# CY8C5888LTI_LP097 register map
File version: 0.1
CY8C58LP
Registers are 8-bit, read-write, no defined reset value unless marked. A register's access mark holds for its fields unless they carry their own. Offsets are from the block's base; lines under a group give offsets from that group; [hi:lo] are bit positions; {n}, {i} and the like mark numbered series; 'fields as' and 'values as' point back to an identical list; <NAME> marks a mode.

## Memory map
0x00000000 RTC

## RTC
Base 0x00000000
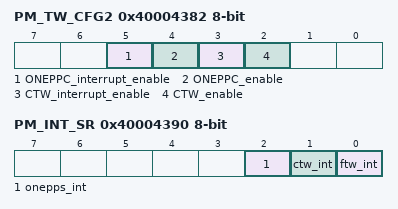
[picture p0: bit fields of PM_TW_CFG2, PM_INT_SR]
0x40004382 PM_TW_CFG2 — Power timers enable and interrupt enable configuration register
  [5] ONEPPC_interrupt_enable — When set and one pulse-per-second is enabled, an interrupt is issued when the pulse occurs
    1=Enabled (The ONEPPC interrupt is issued. Only if ONEPPC is enabled.); 0=Disabled (No ONEPPC interrupt is issued.)
  [4] ONEPPC_enable
    1=Enabled (The ONEPPC is enabled.); 0=Disabled (The ONEPPC is disabled.)
  [3] CTW_interrupt_enable — An interrupt issue when the CTW reaches the selected interval
    1=Enabled (The CTW interrupt is issued. Only if CTW is enabled.); 0=Disabled (No CTW interrupt is issued.)
  [2] CTW_enable
    1=Enabled (The CTW is enabled.); 0=Disabled (The CTW is disabled.)
0x40004390 PM_INT_SR — Power Manager Interrupt Status Register
  [2] onepps_int — When set, a onepps event has occured.
  [1] ctw_int — When set, a limited active ready event has occured
  [0] ftw_int — When set, a fast timewheel event has occured
